# RL6845_IP_SVD register map
Vendor: Realtek
Registers are 32-bit, read-write, reset 0x0 unless marked. A register's access mark holds for its fields unless they carry their own. Offsets are from the block's base; [hi:lo] are bit positions; {n}, {i} and the like mark numbered series.

## AUDIO_REG
Base 0x41106000
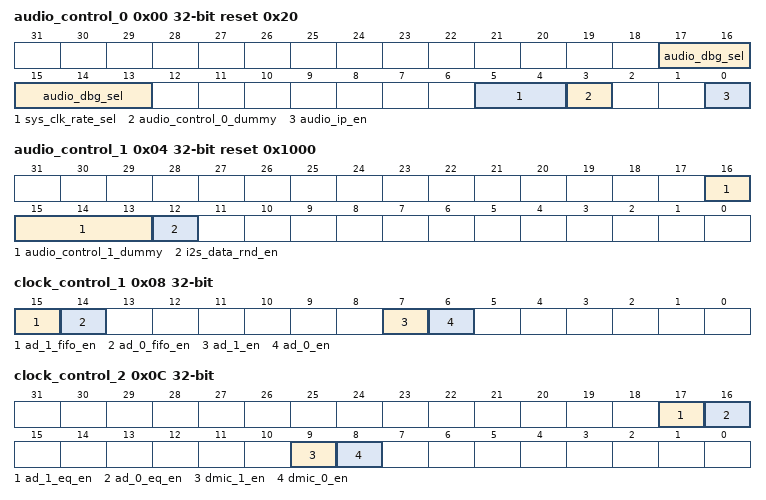
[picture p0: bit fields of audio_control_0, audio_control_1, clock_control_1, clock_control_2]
0x00 audio_control_0 reset 0x20 — Audio Control Register 0
  [17:13] audio_dbg_sel — Debug probe selection
  [5:4] sys_clk_rate_sel — Audio sys_clk selection
  [3] audio_control_0_dummy — DUMMY
  [0] audio_ip_en
0x04 audio_control_1 reset 0x1000 — Audio Control Register 1
  [16:13] audio_control_1_dummy — Dummy
  [12] i2s_data_rnd_en
0x08 clock_control_1 — Clock Control Register 1
  [15] ad_1_fifo_en — ADC channel 1 FIFO clock enable
  [14] ad_0_fifo_en — ADC channel 0 FIFO clock enable
  [7] ad_1_en — ADC channel 1 clock enable
  [6] ad_0_en — ADC channel 0 clock enable
0x0C clock_control_2 — Clock Control Register 2
  [17] ad_1_eq_en — ADC channel 1 EQ clock enable
  [16] ad_0_eq_en — ADC channel 0 EQ clock enable
  [9] dmic_1_en — ADC filter channel 1 clock enable: DMIC path
  [8] dmic_0_en — ADC filter channel 0 clock enable: DMIC path
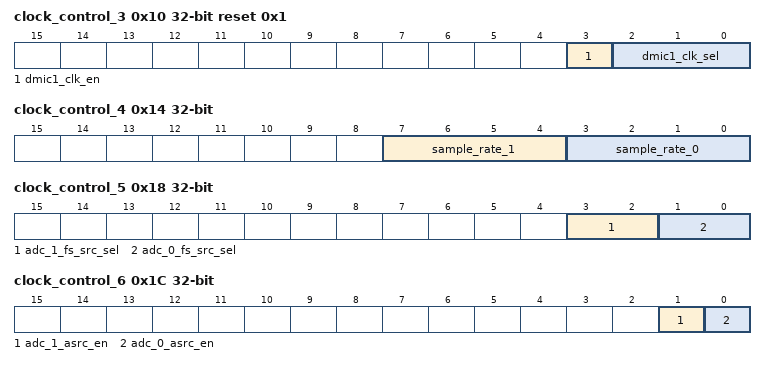
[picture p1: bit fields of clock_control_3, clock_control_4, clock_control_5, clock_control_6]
0x10 clock_control_3 reset 0x1 — Clock Control Register 3
  [3] dmic1_clk_en — Digital microphone clock enable
  [2:0] dmic1_clk_sel — Set clock of digital microphone 3'b000: 5MHz 3'b001: 2.5MHz 3'b010: 1.25MHz 3'b011: 625kHz 3'b100: 312.5kHz 3'b101: Reserved 3'b110: Reserved 3'b111: 769.2kHz
0x14 clock_control_4 — Clock Control Register 4
  [7:4] sample_rate_1 — Set sample rate source 1 4'h0: 48K 4'h1: 96K 4'h2: 192K 4'h3: 32K 4'h4: 176.4K 4'h5: 16K 4'h6: Reserved 4'h7: 8K 4'h8: 44.1K 4'h9: 88.2K 4'ha:24K 4'hb: 12K 4'hc: 22.05K 4'hd: 11.025K 4'he~4'hf: Reserved
  [3:0] sample_rate_0 — Set sample rate source 0 4'h0: 48K 4'h1: 96K 4'h2: 192K 4'h3: 32K 4'h4: 176.4K 4'h5: 16K 4'h6: Reserved 4'h7: 8K 4'h8: 44.1K 4'h9: 88.2K 4'ha:24K 4'hb: 12K 4'hc: 22.05K 4'hd: 11.025K 4'he~4'hf: Reserved
0x18 clock_control_5 — Clock Control Register 5
  [3:2] adc_1_fs_src_sel — Channel 1 ADC path sample rate source selection 2'b00: Source 0 2'b01: Source 1 2'b10: Source 2
  [1:0] adc_0_fs_src_sel — Channel 0 ADC path sample rate source selection 2'b00: Source 0 2'b01: Source 1 2'b10: Source 2
0x1C clock_control_6 — Clock Control Register 6
  [1] adc_1_asrc_en — Channel 1 ADC path ASRC enable 0: Disable 1: Enable If ASRC is enabled, sample_rate becomes useless.
  [0] adc_0_asrc_en — Channel 0 ADC path ASRC enable 0: Disable 1: Enable If ASRC is enabled, sample_rate becomes useless.
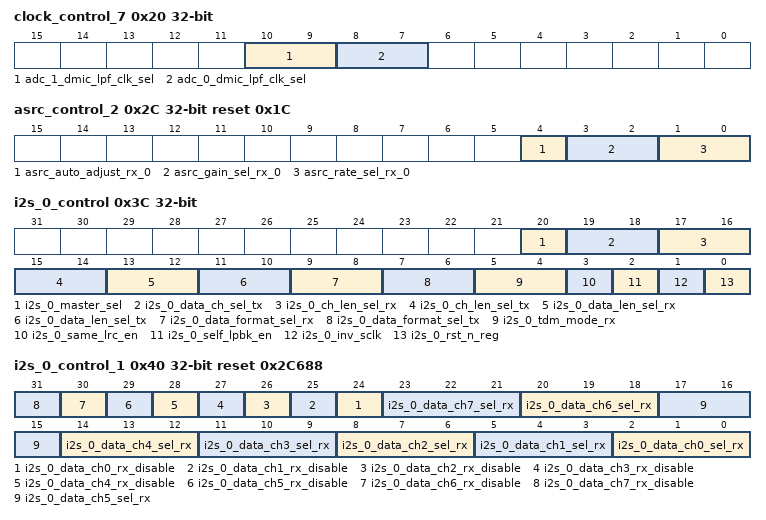
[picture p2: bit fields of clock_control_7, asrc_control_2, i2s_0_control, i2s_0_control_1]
0x20 clock_control_7 — Clock Control Register 7
  [10:9] adc_1_dmic_lpf_clk_sel — Channel 1 ADC path DMIC LPF clock 2'b00: 10M 2'b01: 5M 2'b10: 2.5M 2'b11: 769.2*2K
  [8:7] adc_0_dmic_lpf_clk_sel — Channel 0 ADC path DMIC LPF clock 2'b00: 10M 2'b01: 5M 2'b10: 2.5M 2'b11: 769.2*2K
0x2C asrc_control_2 reset 0x1C — ASRC Control Register 2
  [4] asrc_auto_adjust_rx_0 — HW auto adjust convergence rate 0: Disable 1: Enable
  [3:2] asrc_gain_sel_rx_0 — ASRC convergence rate: larger is faster but more noisy
  [1:0] asrc_rate_sel_rx_0 — 0: fs supports 4kHz ~ 60kHz 1: fs supports 60kHz ~ 120kHz 2/3: Reserved
0x30 asrc_control_3 — ASRC Control Register 3
  [23:0] asrc_sdm_inti_rx_0 — Set initial value of tracked frequency
0x3C i2s_0_control
  [20] i2s_0_master_sel — I2S 0 master source selection 1'b0: internal SPORT 1'b1: external I2S
  [19:18] i2s_0_data_ch_sel_tx — I2S 0 Tx channel data 2'b00: L/R 2'b01: R/L 2'b10: L/L 2'b11: R/R
  [17:16] i2s_0_ch_len_sel_rx — I2S 0 Rx channel length 2'b00: 16 bits 2'b01: 32 bits 2'b10: 24 bits 2'b11: 8 bits
  [15:14] i2s_0_ch_len_sel_tx — I2S 0 Tx channel length 2'b00: 16 bits 2'b01: 32 bits 2'b10: 24 bits 2'b11: 8 bits
  [13:12] i2s_0_data_len_sel_rx — I2S 0 Rx channel data length 2'b00: 16 bits 2'b10: 24 bits 2'b11: 8 bits
  [11:10] i2s_0_data_len_sel_tx — I2S 0 Tx channel data length 2'b00: 16 bits 2'b10: 24 bits 2'b11: 8 bits
  [9:8] i2s_0_data_format_sel_rx — I2S 0 Rx channel data format 2'b00: I2S 2'b01: Left-justified 2'b10: PCM mode A 2'b11: PCM mode B
  [7:6] i2s_0_data_format_sel_tx — I2S 0 Tx channel data format 2'b00: I2S 2'b01: Left-justified 2'b10: PCM mode A 2'b11: PCM mode B
  [5:4] i2s_0_tdm_mode_rx — I2S 0 Rx channel TDM mode 0: 2 channels 1: 4 channels 2/3: Reserved
  [3] i2s_0_same_lrc_en — 1'b1: LRC_TX share to LRC_RX
  [2] i2s_0_self_lpbk_en — 1'b1: internal loopback mode is enabled
  [1] i2s_0_inv_sclk — 1'b1: I2S/PCM bit clock is inverted
  [0] i2s_0_rst_n_reg — 1'b1: rst_n to audio digital IP is de-asserted 1'b0: rst_n to audio digital IP is asserted
0x40 i2s_0_control_1 reset 0x2C688 — I2S 0 Control Register 1
  [n+24] i2s_0_data_ch{n}_rx_disable (n=0..7) — I2S 0 Rx channel data channel {n} 1: disable 0: enable
  [3n+2:3n] i2s_0_data_ch{n}_sel_rx (n=0..7) — I2S 0 Rx channel data channel {n} 0: CH0 1: CH1 2/3/4/5/6/7: reserved
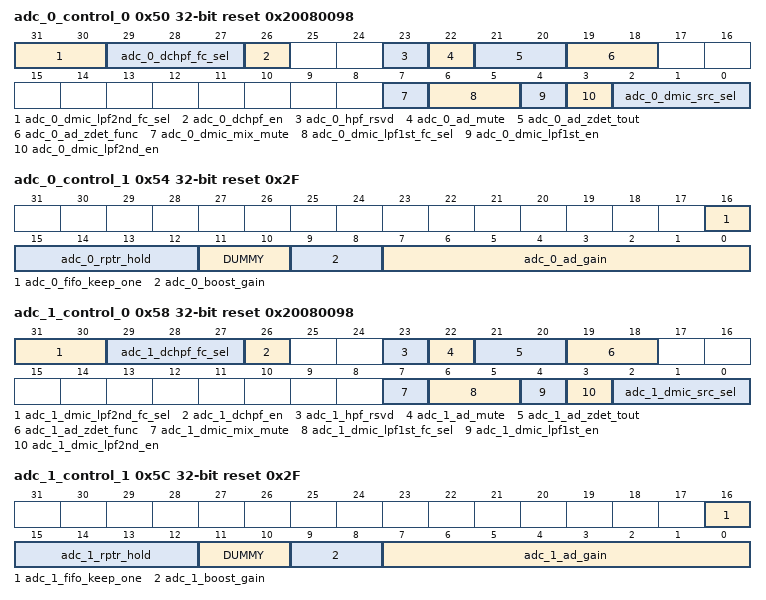
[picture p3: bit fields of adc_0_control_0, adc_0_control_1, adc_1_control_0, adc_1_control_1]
0x50 adc_0_control_0 reset 0x20080098 — ADC Channel 0 Control Register 0
  [31:30] adc_0_dmic_lpf2nd_fc_sel — Uplink Channel 0 DMIC path SRC 2nd LPF FC
  [29:27] adc_0_dchpf_fc_sel — Channel 0 ADC path high pass filter Fc
  [26] adc_0_dchpf_en — Channel 0 ADC path high pass filter enable control (filter DC) 0: Disable 1: Enable
  [23] adc_0_hpf_rsvd — Channel 0 ADC path reserved
  [22] adc_0_ad_mute — Channel 0 ADC path mute 0: Un-Mute 1: Mute
  [21:20] adc_0_ad_zdet_tout — Channel 0 ADC path zero detection time out selection 2'b00: 1024*16 samples 2'b01: 1024*32 samples 2'b10: 1024*64 samples 2'b11: 64 samples
  [19:18] adc_0_ad_zdet_func — Channel 0 ADC path zero detection function selection 2'b00: immediate change 2'b01: zero detection & immediate change 2'b10: zero detection & step 2'b11: zero detection & timeout step
  [7] adc_0_dmic_mix_mute — Channel 0 DMIC input path mute 0: Un-Mute 1: Mute
  [6:5] adc_0_dmic_lpf1st_fc_sel — Channel 0 DMIC path SRC 1st LPF FC
  [4] adc_0_dmic_lpf1st_en — Channel 0 DMIC path SRC 1st LPF control 0: Disable 1: Enable
  [3] adc_0_dmic_lpf2nd_en — Channel 0 DMIC path SRC 2nd LPF control 0: Disable 1: Enable
  [2:0] adc_0_dmic_src_sel — Channel 0 DMIC source selection 3'b000: MIC 1 rising 3'b001: MIC 1 falling 3'b010: MIC 2 rising 3'b011: MIC 2 falling other: reserved
0x54 adc_0_control_1 reset 0x2F — ADC Channel 0 Control Register 1
  [16] adc_0_fifo_keep_one — Channel 0 I2S sample buffering 0: 4 samples 1: 1 sample
  [15:12] adc_0_rptr_hold — Channel 0 I2S read point hold number rptr_hold = (I2S_fs/ad_fs) - 1
  [11:10] DUMMY
  [9:8] adc_0_boost_gain — Channel 0 ADC path boost gain control 00: 0dB 01: 12dB 10: 24dB 11: 36dB
  [7:0] adc_0_ad_gain — Channel 0 ADC digital volume -17.625dB ~ 48dB in 0.375dB step 8'h00: -17.625dB ... 8'h2f: 0dB 8'h30: 0.375dB ... 8'haf: 48dB
0x58 adc_1_control_0 reset 0x20080098 — ADC Channel 1 Control Register 0
  [31:30] adc_1_dmic_lpf2nd_fc_sel — Uplink Channel 1 DMIC path SRC 2nd LPF FC
  [29:27] adc_1_dchpf_fc_sel — Channel 1 ADC path high pass filter Fc
  [26] adc_1_dchpf_en — Channel 1 ADC path high pass filter enable control (filter DC) 0: Disable 1: Enable
  [23] adc_1_hpf_rsvd — Channel 1 ADC path reserved
  [22] adc_1_ad_mute — Channel 1 ADC path mute 0: Un-Mute 1: Mute
  [21:20] adc_1_ad_zdet_tout — Channel 1 ADC path zero detection time out selection 2'b00: 1024*16 samples 2'b01: 1024*32 samples 2'b10: 1024*64 samples 2'b11: 64 samples
  [19:18] adc_1_ad_zdet_func — Channel 1 ADC path zero detection function selection 2'b00: immediate change 2'b01: zero detection & immediate change 2'b10: zero detection & step 2'b11: zero detection & timeout step
  [7] adc_1_dmic_mix_mute — Channel 1 DMIC input path mute 0: Un-Mute 1: Mute
  [6:5] adc_1_dmic_lpf1st_fc_sel — Channel 1 DMIC path SRC 1st LPF FC
  [4] adc_1_dmic_lpf1st_en — Channel 1 DMIC path SRC 1st LPF control 0: Disable 1: Enable
  [3] adc_1_dmic_lpf2nd_en — Channel 1 DMIC path SRC 2nd LPF control 0: Disable 1: Enable
  [2:0] adc_1_dmic_src_sel — Channel 1 DMIC source selection 3'b000: MIC 1 rising 3'b001: MIC 1 falling 3'b010: MIC 2 rising 3'b011: MIC 2 falling other: reserved
0x5C adc_1_control_1 reset 0x2F — ADC Channel 1 Control Register 1
  [16] adc_1_fifo_keep_one — Channel 1 I2S sample buffering 0: 4 samples 1: 1 sample
  [15:12] adc_1_rptr_hold — Channel 1 I2S read point hold number rptr_hold = (I2S_fs/ad_fs) - 1
  [11:10] DUMMY
  [9:8] adc_1_boost_gain — Channel 1 ADC path boost gain control 00: 0dB 01: 12dB 10: 24dB 11: 36dB
  [7:0] adc_1_ad_gain — Channel 1 ADC digital volume -17.625dB ~ 48dB in 0.375dB step 8'h00: -17.625dB ... 8'h2f: 0dB 8'h30: 0.375dB ... 8'haf: 48dB
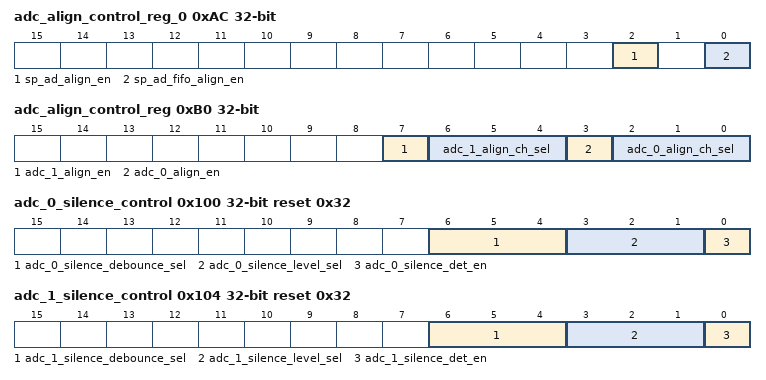
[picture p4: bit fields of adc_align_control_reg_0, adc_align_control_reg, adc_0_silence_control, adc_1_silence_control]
0xAC adc_align_control_reg_0 — ADC Align Control Register 0
  [2] sp_ad_align_en — 1: Uplink channel will align with I2S 0: Disable
  [0] sp_ad_fifo_align_en — 1: Uplink FIFO will align with I2S 0: Disable
0xB0 adc_align_control_reg — ADC Align Control Register
  [7] adc_1_align_en — Uplink CH1 align enable
  [6:4] adc_1_align_ch_sel — Uplink CH1 align channel selection 0: CH0 1: CH1 Others: reserved
  [3] adc_0_align_en — Uplink CH0 align enable
  [2:0] adc_0_align_ch_sel — Uplink CH0 align channel selection 0: CH0 1: CH1 Others: reserved
0x100 adc_0_silence_control reset 0x32 — ADC Channel 0 Silence Control Register
  [6:4] adc_0_silence_debounce_sel — Channel 0 ADC path silence detection debounce (48K) 3'b000: 80ms 3'b001: 160ms 3'b010: 320ms 3'b011: 640ms 3'b100: 1.28s 3'b101: 2.56s 3'b110: 5.12s 3'b111: 0.16ms
  [3:1] adc_0_silence_level_sel — Channel 0 ADC path silence detection threshold 3'b000: -54db 3'b001: -60db 3'b010: -66db 3'b011: -72db 3'b100: -78db 3'b101: -84db 3'b110: -90db 3'b111: -96db
  [0] adc_0_silence_det_en — Channel 0 ADC path silence detection enable 0: Disable 1: Enable
0x104 adc_1_silence_control reset 0x32 — ADC Channel 1 Silence Control Register
  [6:4] adc_1_silence_debounce_sel — Channel 1 ADC path silence detection debounce (48K) 3'b000: 80ms 3'b001: 160ms 3'b010: 320ms 3'b011: 640ms 3'b100: 1.28s 3'b101: 2.56s 3'b110: 5.12s 3'b111: 0.16ms
  [3:1] adc_1_silence_level_sel — Channel 1 ADC path silence detection threshold 3'b000: -54db 3'b001: -60db 3'b010: -66db 3'b011: -72db 3'b100: -78db 3'b101: -84db 3'b110: -90db 3'b111: -96db
  [0] adc_1_silence_det_en — Channel 1 ADC path silence detection enable 0: Disable 1: Enable
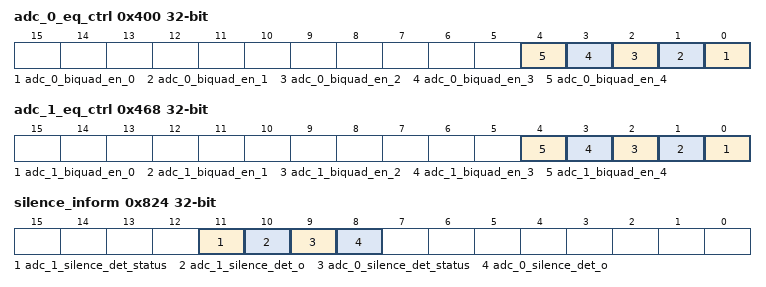
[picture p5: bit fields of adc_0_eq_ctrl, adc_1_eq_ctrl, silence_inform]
0x400 adc_0_eq_ctrl — ADC Channel 0 EQ Control Register
  [n] adc_0_biquad_en_{n} (n=0..4) — ADC channel 0 EQ {n}-band biquad enable 0: disable 1: enable
{0x404+0x14*i} adc_0_biquad_h0_{i} reset 0x2000000 (i=0..4) — ADC Channel 0 EQ Band {i} Biquad H0 Register
  [28:0] adc_0_biquad_h0_{i} — ADC channel 0 EQ {i}-band coef. H0 2's complement in 4.25 format, i.e. the range is from -8~7.99.
{0x408+0x14*i} adc_0_biquad_b1_{i} (i=0..4) — ADC Channel 0 EQ Band {i} Biquad B1 Register
  [28:0] adc_0_biquad_b1_{i} — ADC channel 0 EQ {i}-band coef. B1 2's complement in 4.25 format, i.e. the range is from -8~7.99.
{0x40C+0x14*i} adc_0_biquad_b2_{i} (i=0..4) — ADC Channel 0 EQ Band {i} Biquad B2 Register
  [28:0] adc_0_biquad_b2_{i} — ADC channel 0 EQ {i}-band coef. B2 2's complement in 4.25 format, i.e. the range is from -8~7.99.
{0x410+0x14*i} adc_0_biquad_a1_{i} (i=0..4) — ADC Channel 0 EQ Band {i} Biquad A1 Register
  [28:0] adc_0_biquad_a1_{i} — ADC channel 0 EQ {i}-band coef. A1 2's complement in 4.25 format, i.e. the range is from -8~7.99.
{0x414+0x14*i} adc_0_biquad_a2_{i} (i=0..4) — ADC Channel 0 EQ Band {i} Biquad A2 Register
  [28:0] adc_0_biquad_a2_{i} — ADC channel 0 EQ {i}-band coef. A2 2's complement in 4.25 format, i.e. the range is from -8~7.99.
0x468 adc_1_eq_ctrl — ADC Channel 1 EQ Control Register
  [n] adc_1_biquad_en_{n} (n=0..4) — ADC channel 1 EQ {n}-band biquad enable 0: disable 1: enable
{0x46C+0x14*i} adc_1_biquad_h0_{i} reset 0x2000000 (i=0..4) — ADC Channel 1 EQ Band {i} Biquad H0 Register
  [28:0] adc_1_biquad_h0_{i} — ADC channel 1 EQ {i}-band coef. h0 2's complement in 4.25 format, i.e. the range is from -8~7.99.
{0x470+0x14*i} adc_1_biquad_b1_{i} (i=0..4) — ADC Channel 1 EQ Band {i} Biquad B1 Register
  [28:0] adc_1_biquad_b1_{i} — ADC channel 1 EQ {i}-band coef. b1 2's complement in 4.25 format, i.e. the range is from -8~7.99.
{0x474+0x14*i} adc_1_biquad_b2_{i} (i=0..4) — ADC Channel 1 EQ Band {i} Biquad B2 Register
  [28:0] adc_1_biquad_b2_{i} — ADC channel 1 EQ {i}-band coef. b2 2's complement in 4.25 format, i.e. the range is from -8~7.99.
{0x478+0x14*i} adc_1_biquad_a1_{i} (i=0..4) — ADC Channel 1 EQ Band {i} Biquad A1 Register
  [28:0] adc_1_biquad_a1_{i} — ADC channel 1 EQ {i}-band coef. a1 2's complement in 4.25 format, i.e. the range is from -8~7.99.
{0x47C+0x14*i} adc_1_biquad_a2_{i} (i=0..4) — ADC Channel 1 EQ Band {i} Biquad A2 Register
  [28:0] adc_1_biquad_a2_{i} — ADC channel 1 EQ {i}-band coef. a2 2's complement in 4.25 format, i.e. the range is from -8~7.99.
0x800 ana_read ro
  [0] micbias_oc — The status flag of MICBIAS over-current protection
0x804 adc_0_lpf_rd ro — ADC Channel 0 LPF RD Register
  [18:0] adc_0_lpf_rd — CH 0 ADC LPF out values
0x808 adc_1_lpf_rd ro — ADC Channel 1 LPF RD Register
  [18:0] adc_1_lpf_rd — CH 1 ADC LPF out values
0x824 silence_inform ro
  [11] adc_1_silence_det_status — Ongoing status of adc_1_silencedetection 1'b0: adc_1_silencedetection is resting (clock is gating) 1'b1: adc_1_silencedetection is working
  [10] adc_1_silence_det_o — adc_1_silencedata status (result of silence detection) 1'b0: not adc_1_silencedata 1'b1: adc_1_silenceis detected
  [9] adc_0_silence_det_status — Ongoing status of adc_0_silencedetection 1'b0: adc_0_silencedetection is resting (clock is gating) 1'b1: adc_0_silencedetection is working
  [8] adc_0_silence_det_o — adc_0_silencedata status (result of silence detection) 1'b0: not adc_0_silencedata 1'b1: adc_0_silenceis detected
0x828 audio_ro_dummy1 ro
  [31:0] audio_ro_dummy1 — Dummy register
